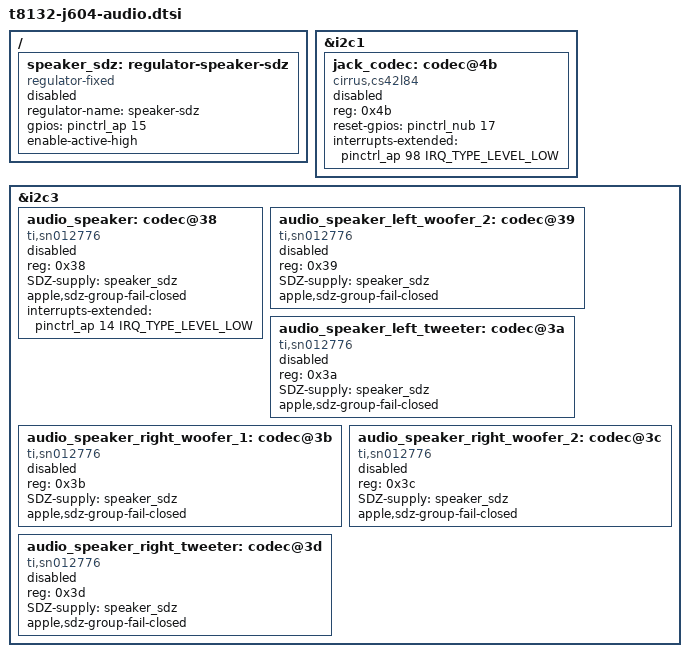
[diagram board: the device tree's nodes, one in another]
// SPDX-License-Identifier: GPL-2.0+ OR MIT
/* J604 audio endpoints. Routing and protection qualification remain separate. */

#include <dt-bindings/gpio/gpio.h>
#include <dt-bindings/interrupt-controller/irq.h>

/ {
	speaker_sdz: regulator-speaker-sdz {
		compatible = "regulator-fixed";
		regulator-name = "speaker-sdz";
		gpios = <&pinctrl_ap 15 GPIO_ACTIVE_HIGH>;
		enable-active-high;
		status = "disabled";
	};
};

&i2c1 {
	jack_codec: codec@4b {
		compatible = "cirrus,cs42l84";
		reg = <0x4b>;
		reset-gpios = <&pinctrl_nub 17 GPIO_ACTIVE_HIGH>;
		interrupts-extended = <&pinctrl_ap 98 IRQ_TYPE_LEVEL_LOW>;
		#sound-dai-cells = <0>;
		status = "disabled";
	};
};

&i2c3 {
	audio_speaker: codec@38 {
		compatible = "ti,sn012776", "ti,tas2764";
		reg = <0x38>;
		SDZ-supply = <&speaker_sdz>;
		apple,sdz-group-fail-closed;
		#sound-dai-cells = <0>;
		interrupts-extended = <&pinctrl_ap 14 IRQ_TYPE_LEVEL_LOW>;
		status = "disabled";
	};

	audio_speaker_left_woofer_2: codec@39 {
		compatible = "ti,sn012776", "ti,tas2764";
		reg = <0x39>;
		SDZ-supply = <&speaker_sdz>;
		apple,sdz-group-fail-closed;
		#sound-dai-cells = <0>;
		status = "disabled";
	};

	audio_speaker_left_tweeter: codec@3a {
		compatible = "ti,sn012776", "ti,tas2764";
		reg = <0x3a>;
		SDZ-supply = <&speaker_sdz>;
		apple,sdz-group-fail-closed;
		#sound-dai-cells = <0>;
		status = "disabled";
	};

	audio_speaker_right_woofer_1: codec@3b {
		compatible = "ti,sn012776", "ti,tas2764";
		reg = <0x3b>;
		SDZ-supply = <&speaker_sdz>;
		apple,sdz-group-fail-closed;
		#sound-dai-cells = <0>;
		status = "disabled";
	};

	audio_speaker_right_woofer_2: codec@3c {
		compatible = "ti,sn012776", "ti,tas2764";
		reg = <0x3c>;
		SDZ-supply = <&speaker_sdz>;
		apple,sdz-group-fail-closed;
		#sound-dai-cells = <0>;
		status = "disabled";
	};

	audio_speaker_right_tweeter: codec@3d {
		compatible = "ti,sn012776", "ti,tas2764";
		reg = <0x3d>;
		SDZ-supply = <&speaker_sdz>;
		apple,sdz-group-fail-closed;
		#sound-dai-cells = <0>;
		status = "disabled";
	};

};
